VERSION ""

NS_ :

BS_:

BU_: XXX DSU HCU EPS IPAS CGW INTERCEPTOR EON BRAKE

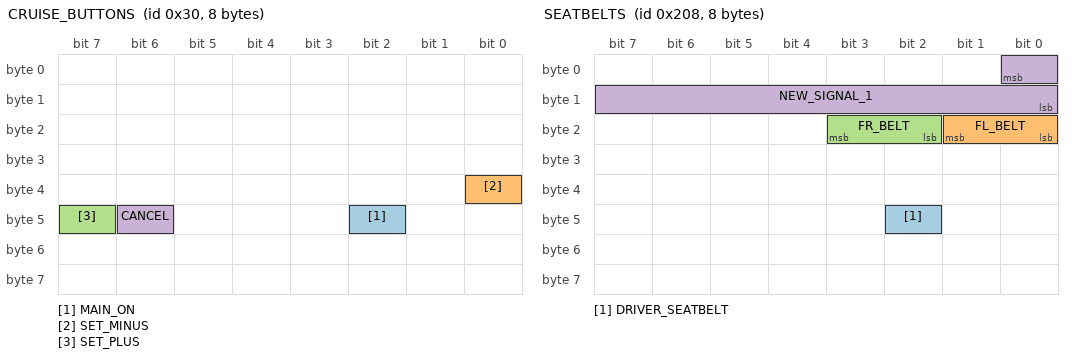
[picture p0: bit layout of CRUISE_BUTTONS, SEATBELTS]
BO_ 48 CRUISE_BUTTONS: 8 XXX
 SG_ MAIN_ON : 42|1@0+ (1,0) [0|1] "" XXX
 SG_ SET_MINUS : 32|1@0+ (1,0) [0|1] "" XXX
 SG_ SET_PLUS : 47|1@0+ (1,0) [0|1] "" XXX
 SG_ CANCEL : 46|1@0+ (1,0) [0|1] "" XXX

BO_ 176 STEER_ANGLE_SENSOR: 8 XXX
 SG_ STEER_ANGLE : 46|15@0- (0.044444444,0) [0|65535] "" XXX

BO_ 320 STEER_TORQUE: 8 XXX
 SG_ DIRECTION : 21|1@0+ (1,0) [0|1] "" XXX
 SG_ DRIVER_TORQUE : 16|9@0+ (1,0) [0|16383] "" XXX

BO_ 128 GAS_BRAKE: 8 XXX
 SG_ BRAKE_PRESSED : 2|1@0+ (1,0) [0|511] "" XXX
 SG_ GAS_PEDAL : 1|10@0+ (1,0) [0|255] "" XXX

BO_ 864 DOORS: 8 XXX
 SG_ DRIVER_DOOR : 16|1@0+ (1,0) [0|1] "" XXX

BO_ 520 SEATBELTS: 8 XXX
 SG_ DRIVER_SEATBELT : 42|1@0+ (1,0) [0|1] "" XXX
 SG_ FL_BELT : 17|2@0+ (1,0) [0|3] "" XXX
 SG_ FR_BELT : 19|2@0+ (1,0) [0|3] "" XXX
 SG_ NEW_SIGNAL_1 : 0|9@0- (1,0) [0|511] "" XXX

BO_ 448 BRAKE_MODULE: 8 XXX
 SG_ BRAKE_PRESSURE : 51|12@0+ (1,0) [0|63] "" XXX

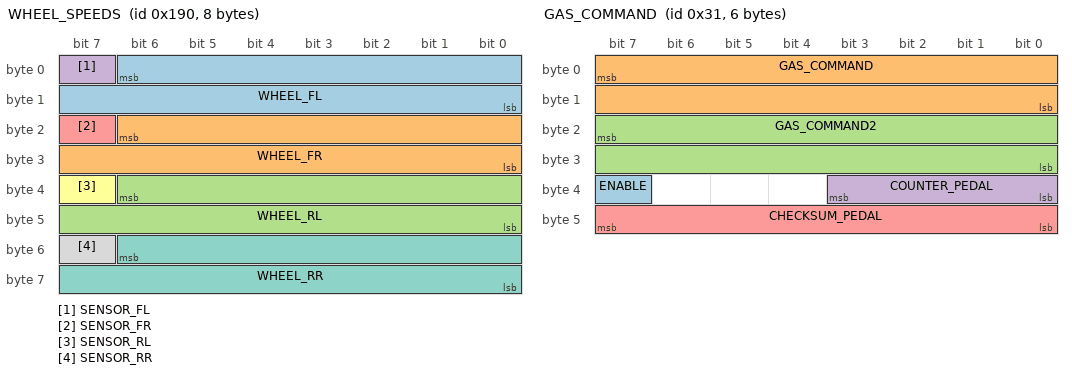
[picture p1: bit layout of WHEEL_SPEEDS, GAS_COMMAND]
BO_ 400 WHEEL_SPEEDS: 8 XXX
 SG_ WHEEL_FL : 6|15@0+ (0.01,0) [0|65535] "" XXX
 SG_ WHEEL_FR : 22|15@0+ (0.01,0) [0|65535] "" XXX
 SG_ WHEEL_RL : 38|15@0+ (0.01,0) [0|65535] "" XXX
 SG_ SENSOR_FL : 7|1@0+ (1,0) [0|1] "" XXX
 SG_ SENSOR_FR : 23|1@0+ (1,0) [0|1] "" XXX
 SG_ SENSOR_RL : 39|1@0+ (1,0) [0|1] "" XXX
 SG_ WHEEL_RR : 54|15@0+ (0.01,0) [0|65535] "" XXX
 SG_ SENSOR_RR : 55|1@0+ (1,0) [0|1] "" XXX

BO_ 16 VSC: 8 XXX
 SG_ STEER_RATE : 35|12@0+ (0.05,0) [0|63] "" XXX

BO_ 224 GEAR_PACKET: 8 XXX
 SG_ GEAR : 37|3@0+ (1,0) [0|7] "" XXX

BO_ 49 GAS_COMMAND: 6 EON
 SG_ ENABLE : 39|1@0+ (1,0) [0|1] "" INTERCEPTOR
 SG_ GAS_COMMAND : 7|16@0+ (0.085,0) [0|1] "" INTERCEPTOR
 SG_ GAS_COMMAND2 : 23|16@0+ (0.17,0) [0|1] "" INTERCEPTOR
 SG_ COUNTER_PEDAL : 35|4@0+ (1,0) [0|15] "" INTERCEPTOR
 SG_ CHECKSUM_PEDAL : 47|8@0+ (1,0) [0|255] "" INTERCEPTOR

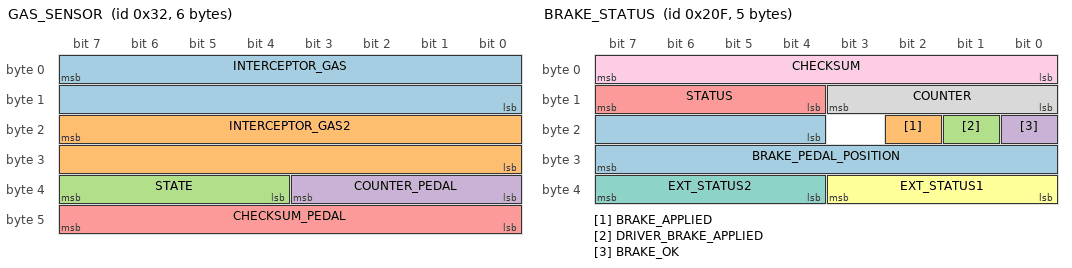
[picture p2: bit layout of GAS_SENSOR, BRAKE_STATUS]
BO_ 50 GAS_SENSOR: 6 INTERCEPTOR
 SG_ INTERCEPTOR_GAS : 7|16@0+ (0.085,0) [0|1] "" EON
 SG_ INTERCEPTOR_GAS2 : 23|16@0+ (0.17,0) [0|1] "" EON
 SG_ STATE : 39|4@0+ (1,0) [0|15] "" EON
 SG_ COUNTER_PEDAL : 35|4@0+ (1,0) [0|15] "" EON
 SG_ CHECKSUM_PEDAL : 47|8@0+ (1,0) [0|255] "" EON

BO_ 80 STEER_COMMAND: 6 XXX
 SG_ STEER_TORQUE_CMD : 7|16@0+ (1,0) [0|1] "" INTERCEPTOR

BO_ 527 BRAKE_STATUS: 5 IBST
 SG_ BRAKE_PEDAL_POSITION : 20|12@1+ (0.015625,-5) [-5|47] "mm" EON
 SG_ BRAKE_APPLIED : 18|1@1+ (1,0) [0|1] "" EON
 SG_ DRIVER_BRAKE_APPLIED : 17|1@1+ (1,0) [0|1] "" EON
 SG_ BRAKE_OK : 16|1@1+ (1,0) [0|1] "" EON
 SG_ STATUS : 12|4@1+ (1,0) [0|15] "" EON
 SG_ EXT_STATUS1 : 32|4@1+ (1,0) [0|15] "" EON
 SG_ EXT_STATUS2 : 36|4@1+ (1,0) [0|15] "" EON
 SG_ COUNTER : 8|4@1+ (1,0) [0|15] "" EON
 SG_ CHECKSUM : 0|8@1+ (1,0) [0|255] "" EON

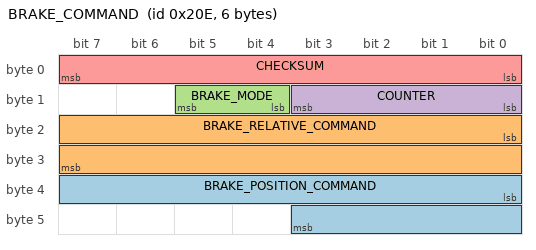
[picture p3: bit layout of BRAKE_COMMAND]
BO_ 526 BRAKE_COMMAND: 6 EON
 SG_ BRAKE_POSITION_COMMAND : 32|12@1+ (0.015625,-5) [-5|47] "mm" IBST
 SG_ BRAKE_RELATIVE_COMMAND : 16|16@1+ (0.0078125,-252) [-252|252] "" IBST
 SG_ BRAKE_MODE : 12|2@1+ (1,0) [0|3] "" IBST
 SG_ COUNTER : 8|4@1+ (1,0) [0|15] "" IBST
 SG_ CHECKSUM : 0|8@1+ (1,0) [0|255] "" IBST

 VAL_ 527 IBOOSTER_BRAKE_APPLIED 1 "Yes" 0 "No" ;
 VAL_ 527 BRAKE_OK 1 "Yes" 0 "No" ;
 VAL_ 527 STATUS 5 "FAULT_TIMEOUT" 4 "FAULT_STARTUP" 3 "FAULT_SCE" 2 "FAULT_SEND" 1 "FAULT_BAD_CHECKSUM" 0 "NO_FAULT" ;
 VAL_ 526 BRAKE_MODE 3 "Reserved" 2 "Position Control" 1 "Relative Control" 0 "Disengadged" ;

 VAL_ 224 GEAR 2 "N" 1 "R" 3 "D" 4 "S" ;
CM_ SG_ 224 GEAR "0=P, 1=R, 2=N, 3=D, 4= S";
